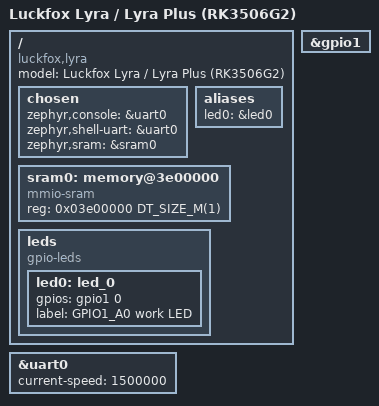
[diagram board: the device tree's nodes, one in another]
/*
 * Luckfox Lyra / Lyra Plus (RK3506G2) - out-of-tree board of 32_03_zephyr/ports. See README.md here.
 * SPDX-License-Identifier: Apache-2.0
 */

/dts-v1/;

#include <arm/rockchip/rk3506.dtsi>
#include <zephyr/dt-bindings/gpio/gpio.h>

/ {
	model = "Luckfox Lyra / Lyra Plus (RK3506G2)";
	compatible = "luckfox,lyra", "rockchip,rk3506";

	chosen {
		zephyr,console = &uart0;
		zephyr,shell-uart = &uart0;
		zephyr,sram = &sram0;
	};

	aliases {
		led0 = &led0;
	};

	sram0: memory@3e00000 {
		device_type = "memory";
		compatible = "mmio-sram";
		reg = <0x03e00000 DT_SIZE_M(1)>;
	};

	leds {
		compatible = "gpio-leds";

		led0: led_0 {
			gpios = <&gpio1 0 GPIO_ACTIVE_HIGH>;
			label = "GPIO1_A0 work LED";
		};
	};
};

&uart0 {
	status = "okay";
	current-speed = <1500000>;
};

&gpio1 {
	status = "okay";
};

